# LargeDummyDevice register map
File version: 1.0
Registers are 32-bit, read-write, no defined reset value unless marked. A register's access mark holds for its fields unless they carry their own. Offsets are from the block's base; [hi:lo] are bit positions.

## PERIPHERAL_61
Base 0x4003C000
0x04 REG_1 — Register 1
  [29] FIELD_20, [28:25] FIELD_8, [26:24] FIELD_1, [28:24] FIELD_4, [25:23] FIELD_6, [26:23] FIELD_11, [23:22] FIELD_14, [24:21] FIELD_5, [25:21] FIELD_13, [14:13] FIELD_15, [17:13] FIELD_18, [12:11] FIELD_2, [11] FIELD_17, [12:11] FIELD_19, [10] FIELD_7, [12:9] FIELD_21, [11:8] FIELD_9, [11:7] FIELD_3, [9:7] FIELD_16, [7:6] FIELD_12, [6:2] FIELD_22, [2:0] FIELD_10
0x08 REG_2 — Register 2
  [33:30] FIELD_7, [30] FIELD_13, [31:30] FIELD_18, [29] FIELD_1, [27] FIELD_10, [30:26] FIELD_6, [27:25] FIELD_19, [22] FIELD_2, [18:17] FIELD_3, [21:17] FIELD_11, [18:16] FIELD_5, [17:15] FIELD_26, [14] FIELD_8, [16:14] FIELD_14, [17:14] FIELD_25, [16:13] FIELD_16, [12] FIELD_24, [11] FIELD_12, [13:11] FIELD_21, [15:11] FIELD_22, [14:11] FIELD_23, [8:5] FIELD_17, [5] FIELD_20, [2:1] FIELD_9, [0] FIELD_4, [3:0] FIELD_15
0x0C REG_3 — Register 3
  [35:31] FIELD_21, [35:31] FIELD_27, [31:30] FIELD_2, [33:30] FIELD_32, [30:29] FIELD_1, [33:29] FIELD_30, [31:29] FIELD_31, [27] FIELD_23, [26] FIELD_11, [29:25] FIELD_14, [24:22] FIELD_29, [22:21] FIELD_18, [20:18] FIELD_9, [20:17] FIELD_20, [16:14] FIELD_4, [14] FIELD_6, [16:12] FIELD_5, [14:12] FIELD_10, [10] FIELD_25, [11:9] FIELD_13, [13:9] FIELD_22, [11:8] FIELD_19, [12:8] FIELD_26, [10:7] FIELD_12, [10:7] FIELD_16, [9:7] FIELD_24, [11:7] FIELD_28, [8:5] FIELD_3, [7:5] FIELD_17, [3] FIELD_7, [4:3] FIELD_8, [4:1] FIELD_15
0x10 REG_4 — Register 4
  [30] FIELD_1, [30:29] FIELD_3, [31:27] FIELD_9, [27] FIELD_16, [27] FIELD_20, [27:26] FIELD_10, [26:24] FIELD_15, [24:23] FIELD_26, [26:22] FIELD_2, [25:22] FIELD_4, [18] FIELD_18, [21:17] FIELD_8, [19:16] FIELD_22, [16:14] FIELD_14, [14] FIELD_17, [14:12] FIELD_13, [12] FIELD_19, [12] FIELD_23, [13:11] FIELD_21, [14:11] FIELD_24, [9:7] FIELD_11, [8:7] FIELD_27, [3:2] FIELD_5, [5:2] FIELD_7, [2:1] FIELD_6, [4:1] FIELD_12, [2:0] FIELD_25
0x14 REG_5 — Register 5
  [28:26] FIELD_4, [26:25] FIELD_3, [24:22] FIELD_2, [24:20] FIELD_1
0x18 REG_6 — Register 6
  [16:14] FIELD_6, [14:11] FIELD_1, [15:11] FIELD_7, [12:10] FIELD_5, [9:7] FIELD_3, [7:4] FIELD_4, [0] FIELD_2
0x1C REG_7 — Register 7
  [29:26] FIELD_4, [22] FIELD_5, [22:19] FIELD_6, [16:12] FIELD_1, [9:8] FIELD_2, [10:6] FIELD_3
0x20 REG_8 — Register 8
  [32:31] FIELD_31, [30] FIELD_28, [33:29] FIELD_18, [29:27] FIELD_6, [29:27] FIELD_9, [22:21] FIELD_2, [22:19] FIELD_14, [20:19] FIELD_19, [20:19] FIELD_24, [21:19] FIELD_29, [19] FIELD_30, [22:18] FIELD_7, [21:18] FIELD_17, [22:18] FIELD_26, [21:17] FIELD_10, [17:15] FIELD_13, [17:15] FIELD_22, [17:14] FIELD_5, [16:13] FIELD_1, [15:13] FIELD_20, [16:13] FIELD_25, [12] FIELD_21, [11:10] FIELD_3, [11:10] FIELD_16, [8] FIELD_27, [9:5] FIELD_23, [8:4] FIELD_8, [3] FIELD_12, [4:3] FIELD_15, [5:2] FIELD_11, [0] FIELD_4
0x24 REG_9 — Register 9
  [30:28] FIELD_3, [32:28] FIELD_5, [26:25] FIELD_9, [27:23] FIELD_7, [24:21] FIELD_2, [13] FIELD_6, [13:9] FIELD_1, [8:7] FIELD_10, [8:6] FIELD_8, [6:5] FIELD_4
0x28 REG_10 — Register 10
  [35:31] FIELD_4, [25:22] FIELD_6, [17] FIELD_3, [16:15] FIELD_7, [13:11] FIELD_2, [9] FIELD_1, [6:4] FIELD_5
0x2C REG_11 — Register 11
  [33:31] FIELD_3, [32:31] FIELD_5, [35:31] FIELD_10, [32:29] FIELD_13, [29:26] FIELD_6, [29:25] FIELD_1, [25] FIELD_18, [27:23] FIELD_16, [23] FIELD_20, [19:16] FIELD_7, [14:12] FIELD_4, [14:10] FIELD_9, [10:7] FIELD_14, [6:5] FIELD_15, [8:5] FIELD_17, [7:4] FIELD_2, [2] FIELD_8, [5:2] FIELD_12, [2] FIELD_19, [3:0] FIELD_11
0x30 REG_12 — Register 12
  [33:30] FIELD_24, [32:29] FIELD_4, [32:28] FIELD_15, [31:28] FIELD_16, [30:26] FIELD_17, [29:25] FIELD_22, [24] FIELD_12, [21:20] FIELD_31, [21:19] FIELD_18, [23:19] FIELD_20, [21:19] FIELD_25, [22:18] FIELD_7, [20:18] FIELD_19, [18:17] FIELD_1, [16] FIELD_9, [17:16] FIELD_14, [19:16] FIELD_23, [15:13] FIELD_8, [16:13] FIELD_13, [13:10] FIELD_2, [11:10] FIELD_5, [13:10] FIELD_28, [9] FIELD_26, [11:9] FIELD_30, [8:7] FIELD_21, [8:6] FIELD_6, [7:4] FIELD_11, [6:4] FIELD_27, [6:3] FIELD_10, [6:2] FIELD_3, [0] FIELD_29
0x34 REG_13 — Register 13
  [35:31] FIELD_21, [31:28] FIELD_20, [31:27] FIELD_14, [31:27] FIELD_23, [27:26] FIELD_19, [25] FIELD_9, [27:25] FIELD_16, [27:25] FIELD_29, [28:24] FIELD_26, [24:23] FIELD_2, [22] FIELD_5, [23:19] FIELD_7, [18] FIELD_1, [19:18] FIELD_28, [21:17] FIELD_4, [19:17] FIELD_10, [20:17] FIELD_17, [15] FIELD_11, [15] FIELD_13, [18:15] FIELD_22, [15] FIELD_24, [12:11] FIELD_6, [14:10] FIELD_3, [11:10] FIELD_12, [14:10] FIELD_27, [7:6] FIELD_15, [10:6] FIELD_18, [10:6] FIELD_25, [5] FIELD_8, [7:4] FIELD_30
0x38 REG_14 — Register 14
  [32:31] FIELD_9, [25] FIELD_4, [25:24] FIELD_10, [27:23] FIELD_6, [23:21] FIELD_3, [20] FIELD_14, [21:18] FIELD_5, [16] FIELD_2, [16:15] FIELD_16, [15:13] FIELD_8, [14:13] FIELD_12, [12:11] FIELD_13, [10:8] FIELD_15, [8:7] FIELD_1, [10:7] FIELD_7, [3:1] FIELD_11
0x3C REG_15 — Register 15
  [31:29] FIELD_11, [27:26] FIELD_12, [28:25] FIELD_15, [28:24] FIELD_14, [26:23] FIELD_6, [27:23] FIELD_10, [20] FIELD_2, [18] FIELD_1, [17:15] FIELD_8, [13:12] FIELD_9, [9] FIELD_5, [12:9] FIELD_13, [6:5] FIELD_4, [8:5] FIELD_7, [4:3] FIELD_3
0x40 REG_16 — Register 16
  [31:29] FIELD_4, [33:29] FIELD_6, [14:10] FIELD_5, [11:8] FIELD_1, [8:4] FIELD_2, [5:3] FIELD_3
0x44 REG_17 — Register 17
  [31:29] FIELD_15, [27:26] FIELD_19, [27:26] FIELD_25, [24:23] FIELD_12, [26:22] FIELD_14, [21] FIELD_9, [20:19] FIELD_16, [20:19] FIELD_21, [20:18] FIELD_24, [16:15] FIELD_4, [16:15] FIELD_11, [15] FIELD_23, [14:12] FIELD_6, [12] FIELD_13, [11:7] FIELD_18, [7:5] FIELD_2, [9:5] FIELD_5, [4] FIELD_7, [8:4] FIELD_17, [4] FIELD_22, [6:3] FIELD_3, [2] FIELD_1, [3:1] FIELD_8, [1] FIELD_10, [1:0] FIELD_20
0x48 REG_18 — Register 18
  [35:31] FIELD_11, [23] FIELD_2, [25:23] FIELD_10, [25:22] FIELD_6, [19:15] FIELD_12, [17:13] FIELD_7, [14:11] FIELD_5, [11:9] FIELD_1, [11:9] FIELD_3, [8:6] FIELD_9, [2] FIELD_8, [2:1] FIELD_4
0x4C REG_19 — Register 19
  [33:29] FIELD_8, [30:27] FIELD_9, [25:23] FIELD_3, [26:22] FIELD_7, [20:18] FIELD_2, [18:17] FIELD_4, [19:15] FIELD_10, [16:13] FIELD_6, [8] FIELD_5, [9:5] FIELD_1
0x50 REG_20 — Register 20
  [32:30] FIELD_17, [32:29] FIELD_4, [33:29] FIELD_16, [31:28] FIELD_7, [27:26] FIELD_2, [27:24] FIELD_14, [21] FIELD_5, [20:18] FIELD_23, [19:17] FIELD_6, [18:15] FIELD_8, [19:15] FIELD_25, [16:14] FIELD_15, [15:14] FIELD_21, [15:13] FIELD_12, [16:12] FIELD_10, [13:12] FIELD_20, [11] FIELD_11, [10] FIELD_13, [14:10] FIELD_22, [12:9] FIELD_3, [10:9] FIELD_24, [9:6] FIELD_1, [9:5] FIELD_18, [1] FIELD_19, [1:0] FIELD_9
0x54 REG_21 — Register 21
  [32:31] FIELD_6, [30:29] FIELD_5, [26] FIELD_4, [29:25] FIELD_3, [24:23] FIELD_1, [23:20] FIELD_7, [7:3] FIELD_2
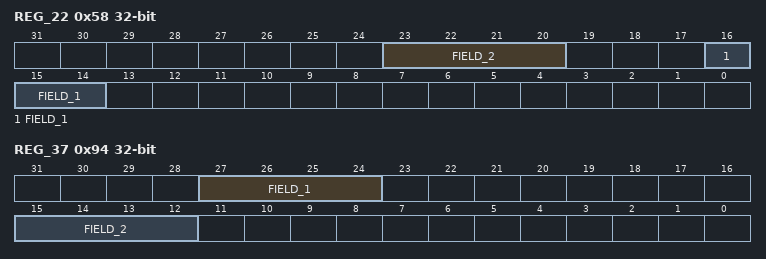
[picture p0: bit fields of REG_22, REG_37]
0x58 REG_22 — Register 22
  [23:20] FIELD_2, [16:14] FIELD_1
0x5C REG_23 — Register 23
  [33:31] FIELD_9, [32:28] FIELD_1, [32:28] FIELD_2, [21] FIELD_5, [24:20] FIELD_7, [23:20] FIELD_13, [18:15] FIELD_6, [15:13] FIELD_10, [15:11] FIELD_4, [11:10] FIELD_12, [13:9] FIELD_8, [8] FIELD_14, [8:5] FIELD_11, [5:2] FIELD_3
0x60 REG_24 — Register 24
  [31:28] FIELD_3, [25] FIELD_8, [25:23] FIELD_1, [24:20] FIELD_4, [21:19] FIELD_10, [21:17] FIELD_7, [15:13] FIELD_11, [8:7] FIELD_12, [7:5] FIELD_6, [6:4] FIELD_9, [3:1] FIELD_2, [4:0] FIELD_5
0x64 REG_25 — Register 25
  [32:31] FIELD_4, [30] FIELD_10, [28] FIELD_1, [32:28] FIELD_5, [29:28] FIELD_7, [32:28] FIELD_8, [26:24] FIELD_17, [23] FIELD_12, [26:23] FIELD_14, [21] FIELD_11, [22:20] FIELD_3, [23:20] FIELD_13, [20] FIELD_20, [20] FIELD_21, [23:20] FIELD_24, [17:14] FIELD_16, [10:8] FIELD_18, [7] FIELD_2, [6] FIELD_22, [4:2] FIELD_6, [3:1] FIELD_23, [0] FIELD_9, [1:0] FIELD_15, [3:0] FIELD_19
0x68 REG_26 — Register 26
  [31] FIELD_6, [32:30] FIELD_7, [31:29] FIELD_23, [28] FIELD_22, [28] FIELD_27, [29:26] FIELD_9, [26:25] FIELD_2, [28:24] FIELD_5, [25:24] FIELD_21, [23:19] FIELD_4, [22:18] FIELD_11, [15:13] FIELD_18, [16:12] FIELD_1, [13:12] FIELD_26, [12:10] FIELD_24, [9] FIELD_13, [10:8] FIELD_10, [10:8] FIELD_19, [11:7] FIELD_15, [10:6] FIELD_16, [9:6] FIELD_25, [8:5] FIELD_14, [5:3] FIELD_3, [5:3] FIELD_17, [2] FIELD_12, [4:2] FIELD_28, [1] FIELD_20, [1:0] FIELD_8
0x6C REG_27 — Register 27
  [35:31] FIELD_10, [27:24] FIELD_5, [22] FIELD_15, [21:20] FIELD_7, [21:19] FIELD_17, [18:17] FIELD_16, [18:14] FIELD_12, [16:13] FIELD_9, [12:9] FIELD_1, [13:9] FIELD_6, [8:7] FIELD_3, [7] FIELD_8, [9:5] FIELD_18, [7:4] FIELD_4, [4:3] FIELD_2, [3] FIELD_13, [3:1] FIELD_11, [4:0] FIELD_14
0x70 REG_28 — Register 28
  [20:17] FIELD_3, [13:11] FIELD_1, [12:9] FIELD_2, [9] FIELD_4
0x74 REG_29 — Register 29
  [35:31] FIELD_17, [29] FIELD_1, [29:26] FIELD_2, [23:22] FIELD_16, [24:21] FIELD_8, [21] FIELD_14, [25:21] FIELD_18, [20:18] FIELD_9, [17:16] FIELD_12, [19:15] FIELD_4, [8:6] FIELD_5, [6:5] FIELD_7, [7:4] FIELD_3, [5:3] FIELD_13, [5:2] FIELD_11, [2:0] FIELD_6, [1:0] FIELD_10, [4:0] FIELD_15
0x78 REG_30 — Register 30
  [32:31] FIELD_3, [34:31] FIELD_15, [31:29] FIELD_9, [27:24] FIELD_12, [25:23] FIELD_8, [21:20] FIELD_5, [22:19] FIELD_11, [20:18] FIELD_10, [18:15] FIELD_4, [15:14] FIELD_14, [13:12] FIELD_1, [11:9] FIELD_7, [10:7] FIELD_6, [6:4] FIELD_2, [7:3] FIELD_16, [4:0] FIELD_13
0x7C REG_31 — Register 31
  [32:28] FIELD_15, [27] FIELD_1, [27] FIELD_18, [24:23] FIELD_11, [24:23] FIELD_19, [24:22] FIELD_3, [21:20] FIELD_9, [17] FIELD_16, [17:15] FIELD_4, [16:15] FIELD_8, [15:13] FIELD_17, [14:10] FIELD_2, [11:7] FIELD_12, [8:6] FIELD_5, [6:5] FIELD_7, [6:4] FIELD_13, [8:4] FIELD_14, [3:1] FIELD_10, [3:0] FIELD_6
0x80 REG_32 — Register 32
  [31:28] FIELD_1, [28] FIELD_2, [32:28] FIELD_14, [27:26] FIELD_17, [25:23] FIELD_5, [25:23] FIELD_19, [23:22] FIELD_4, [25:22] FIELD_20, [21:19] FIELD_21, [19:15] FIELD_7, [18:15] FIELD_9, [16:14] FIELD_10, [12] FIELD_6, [11] FIELD_11, [11] FIELD_18, [10:8] FIELD_3, [9:8] FIELD_13, [11:8] FIELD_23, [5:4] FIELD_8, [6:4] FIELD_16, [5:1] FIELD_22, [3:0] FIELD_12, [0] FIELD_15
0x84 REG_33 — Register 33
  [31] FIELD_9, [33:30] FIELD_11, [28] FIELD_10, [29:26] FIELD_15, [27:25] FIELD_8, [24:23] FIELD_16, [25:23] FIELD_23, [25:21] FIELD_6, [21:20] FIELD_26, [24:20] FIELD_28, [22:20] FIELD_30, [18] FIELD_22, [20:17] FIELD_14, [19:17] FIELD_24, [19:15] FIELD_5, [19:15] FIELD_25, [18:14] FIELD_12, [17:13] FIELD_31, [13:12] FIELD_1, [12] FIELD_20, [13:11] FIELD_3, [14:11] FIELD_21, [8:7] FIELD_7, [7] FIELD_17, [9:7] FIELD_29, [6:4] FIELD_18, [7:3] FIELD_4, [7:3] FIELD_13, [2:1] FIELD_2, [2:1] FIELD_19, [3:0] FIELD_27
0x88 REG_34 — Register 34
  [29:27] FIELD_1, [26] FIELD_2, [24] FIELD_3, [23] FIELD_7, [20:19] FIELD_8, [20:17] FIELD_4, [14:13] FIELD_5, [10:9] FIELD_6
0x8C REG_35 — Register 35
  [26:24] FIELD_6, [25:23] FIELD_10, [24:23] FIELD_11, [21:19] FIELD_4, [19] FIELD_8, [21:18] FIELD_15, [15] FIELD_7, [15:14] FIELD_3, [16:12] FIELD_13, [12:10] FIELD_2, [11:9] FIELD_14, [5] FIELD_16, [8:4] FIELD_1, [5:2] FIELD_5, [1:0] FIELD_9, [1:0] FIELD_12
0x90 REG_36 — Register 36
  [34:30] FIELD_1, [32:28] FIELD_6, [22:20] FIELD_4, [20] FIELD_11, [22:19] FIELD_3, [21:17] FIELD_7, [19:15] FIELD_10, [14] FIELD_5, [11] FIELD_9, [11:10] FIELD_2, [12:10] FIELD_12, [1:0] FIELD_8
0x94 REG_37 — Register 37
  [27:24] FIELD_1, [15:12] FIELD_2
0x98 REG_38 — Register 38
  [32:30] FIELD_7, [29] FIELD_1, [28:27] FIELD_8, [24:21] FIELD_6, [22:18] FIELD_4, [20:18] FIELD_10, [18:16] FIELD_12, [17:15] FIELD_9, [17:14] FIELD_15, [16:12] FIELD_13, [12:10] FIELD_2, [10] FIELD_5, [13:10] FIELD_14, [8] FIELD_3, [1:0] FIELD_11, [1:0] FIELD_16
0x9C REG_39 — Register 39
  [31] FIELD_11, [35:31] FIELD_12, [28:26] FIELD_3, [28:25] FIELD_8, [25:24] FIELD_10, [24] FIELD_21, [23:21] FIELD_5, [21] FIELD_19, [21:18] FIELD_4, [17] FIELD_6, [18:15] FIELD_2, [14] FIELD_7, [13:11] FIELD_20, [15:11] FIELD_22, [14:10] FIELD_1, [11:8] FIELD_15, [11:7] FIELD_9, [7] FIELD_17, [8:4] FIELD_13, [4:2] FIELD_14, [3:2] FIELD_23, [4:1] FIELD_18, [1:0] FIELD_16
0xA0 REG_40 — Register 40
  [35:31] FIELD_1, [30] FIELD_7, [34:30] FIELD_12, [26] FIELD_11, [23:21] FIELD_8, [20:18] FIELD_6, [18:15] FIELD_10, [10:9] FIELD_5, [9:8] FIELD_3, [8] FIELD_9, [6] FIELD_4, [7:4] FIELD_2
0xA4 REG_41 — Register 41
  [34:31] FIELD_24, [31:30] FIELD_23, [30:28] FIELD_2, [29:28] FIELD_8, [23] FIELD_4, [23] FIELD_6, [22] FIELD_31, [22:21] FIELD_30, [21:20] FIELD_5, [20:19] FIELD_22, [22:18] FIELD_18, [20:18] FIELD_21, [18:17] FIELD_15, [20:17] FIELD_26, [18:16] FIELD_20, [18:15] FIELD_9, [15] FIELD_12, [14:12] FIELD_28, [10] FIELD_13, [10:8] FIELD_1, [8:7] FIELD_7, [9:6] FIELD_19, [7:5] FIELD_3, [6:5] FIELD_10, [4:3] FIELD_11, [3:1] FIELD_14, [2:1] FIELD_17, [3:1] FIELD_27, [1] FIELD_29, [3:0] FIELD_16, [2:0] FIELD_25
0xA8 REG_42 — Register 42
  [26] FIELD_1, [26] FIELD_3, [24:22] FIELD_2, [20:17] FIELD_4
0xAC REG_43 — Register 43
  [34:31] FIELD_1, [33:29] FIELD_7, [31:27] FIELD_2, [29:27] FIELD_3, [30:27] FIELD_8, [21] FIELD_4, [23:21] FIELD_9, [20:17] FIELD_12, [15:14] FIELD_6, [14:13] FIELD_10, [13] FIELD_13, [12:10] FIELD_5, [9:8] FIELD_11
0xB0 REG_44 — Register 44
  [32:30] FIELD_22, [29] FIELD_15, [32:28] FIELD_24, [28:26] FIELD_17, [27:26] FIELD_19, [25] FIELD_9, [26:24] FIELD_4, [24] FIELD_5, [25:21] FIELD_21, [23:19] FIELD_8, [19:17] FIELD_7, [19:15] FIELD_20, [16:13] FIELD_12, [16:12] FIELD_6, [12:10] FIELD_2, [12:10] FIELD_10, [9] FIELD_14, [12:8] FIELD_18, [9:7] FIELD_1, [8:7] FIELD_11, [8:6] FIELD_13, [6:4] FIELD_16, [4:2] FIELD_3, [2] FIELD_23
